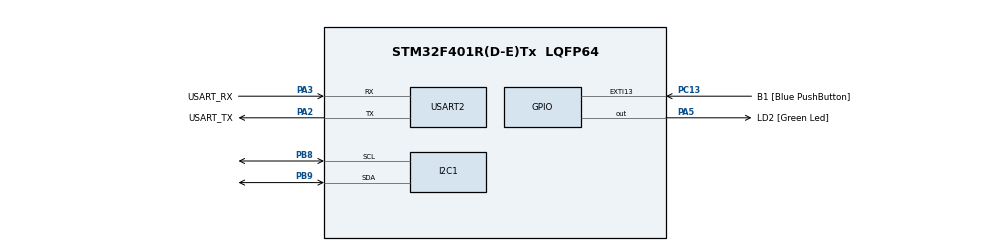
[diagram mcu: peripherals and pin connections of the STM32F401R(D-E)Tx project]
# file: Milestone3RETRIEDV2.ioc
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Mcu.Family=STM32F4
Mcu.Name=STM32F401R(D-E)Tx
Mcu.Package=LQFP64
NVIC.PriorityGroup=NVIC_PRIORITYGROUP_4
PA13.GPIO_Label=TMS
PA13.Mode=Trace_Asynchronous_SW
PA13.Signal=SYS_JTMS-SWDIO
PA14.GPIO_Label=TCK
PA14.Mode=Trace_Asynchronous_SW
PA14.Signal=SYS_JTCK-SWCLK
PA2.GPIO_Label=USART_TX
PA2.GPIO_Mode=GPIO_MODE_AF_PP
PA2.GPIO_PuPd=GPIO_NOPULL
PA2.GPIO_Speed=GPIO_SPEED_FREQ_LOW
PA2.Mode=Asynchronous
PA2.Signal=USART2_TX
PA3.GPIO_Label=USART_RX
PA3.GPIO_Mode=GPIO_MODE_AF_PP
PA3.GPIO_PuPd=GPIO_NOPULL
PA3.GPIO_Speed=GPIO_SPEED_FREQ_LOW
PA3.Mode=Asynchronous
PA3.Signal=USART2_RX
PA5.GPIO_Label=LD2 [Green Led]
PA5.GPIO_Mode=GPIO_MODE_OUTPUT_PP
PA5.GPIO_PuPd=GPIO_NOPULL
PA5.GPIO_Speed=GPIO_SPEED_FREQ_LOW
PA5.Signal=GPIO_Output
PB3.GPIO_Label=SWO
PB3.Mode=Trace_Asynchronous_SW
PB3.Signal=SYS_JTDO-SWO
PB8.Mode=I2C
PB8.Signal=I2C1_SCL
PB9.Mode=I2C
PB9.Signal=I2C1_SDA
PC13-ANTI_TAMP.GPIO_Label=B1 [Blue PushButton]
PC13-ANTI_TAMP.GPIO_ModeDefaultEXTI=GPIO_MODE_IT_FALLING
PC13-ANTI_TAMP.GPIO_PuPd=GPIO_NOPULL
PC13-ANTI_TAMP.Signal=GPXTI13
PC14-OSC32_IN.Mode=LSE-External-Oscillator
PC14-OSC32_IN.Signal=RCC_OSC32_IN
PC15-OSC32_OUT.Mode=LSE-External-Oscillator
PC15-OSC32_OUT.Signal=RCC_OSC32_OUT
PH0\ -\ OSC_IN.Mode=HSE-External-Clock-Source
PH0\ -\ OSC_IN.Signal=RCC_OSC_IN
PH1\ -\ OSC_OUT.Mode=HSE-External-Clock-Source
PH1\ -\ OSC_OUT.Signal=RCC_OSC_OUT
ProjectManager.HeapSize=0x200
ProjectManager.StackSize=0x400
ProjectManager.TargetToolchain=Makefile
RCC.48MHZClocksFreq_Value=48000000
RCC.AHBFreq_Value=84000000
RCC.APB1CLKDivider=RCC_HCLK_DIV2
RCC.APB1Freq_Value=42000000
RCC.APB1TimFreq_Value=84000000
RCC.APB2Freq_Value=84000000
RCC.APB2TimFreq_Value=84000000
RCC.CortexFreq_Value=84000000
RCC.HCLKFreq_Value=84000000
RCC.HSE_VALUE=8000000
RCC.HSI_VALUE=16000000
RCC.PLLN=336
RCC.PLLP=RCC_PLLP_DIV4
RCC.PLLQ=7
RCC.SYSCLKFreq_VALUE=84000000
RCC.SYSCLKSource=RCC_SYSCLKSOURCE_PLLCLK
RCC.VCOOutputFreq_Value=336000000
USART2.VirtualMode=VM_ASYNC
board=NUCLEO-F401RE

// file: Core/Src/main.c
/* USER CODE BEGIN Header */
/**
  ******************************************************************************
  * @file           : main.c
  * @brief          : Main program body
  ******************************************************************************
  * @attention
  *
  * Copyright (c) 2026 STMicroelectronics.
  * All rights reserved.
  *
  * This software is licensed under terms that can be found in the LICENSE file
  * in the root directory of this software component.
  * If no LICENSE file comes with this software, it is provided AS-IS.
  *
  ******************************************************************************
  */
/* USER CODE END Header */
#include "main.h"
#include <string.h>
#include <stddef.h>
#include <stdbool.h>

void SystemClock_Config(void);
static void MX_GPIO_Init(void);
static void MX_I2C1_Init(void);
static void MX_USART2_UART_Init(void);
void UART_SendAndReadData(USART_TypeDef *USARTX, const uint8_t *data, size_t length);
void I2C_Bus_Recovery();

typedef enum {
  ERROR_TIMEOUT,
  ERROR_NACK,
  ERROR_BUS_STUCK,
  I2C_SUCCESS
  } I2C_Status;

  I2C_Status I2C_Wait_With_Timeout(uint32_t, uint32_t);

#define I2C_TIMEOUT_CYCLES 144000
int main(void)
{

  /* MCU Configuration--------------------------------------------------------*/

  /* Reset of all peripherals, Initializes the Flash interface and the Systick. */
  LL_APB2_GRP1_EnableClock(LL_APB2_GRP1_PERIPH_SYSCFG);
  LL_APB1_GRP1_EnableClock(LL_APB1_GRP1_PERIPH_PWR);

  /* System interrupt init*/
  NVIC_SetPriorityGrouping(NVIC_PRIORITYGROUP_4);

  /* Configure the system clock */
  SystemClock_Config();

  /* Initialize all configured peripherals */
  MX_GPIO_Init();
  MX_I2C1_Init();
  MX_USART2_UART_Init();

  CoreDebug->DEMCR |= CoreDebug_DEMCR_TRCENA_Msk;
  DWT->CTRL |= DWT_CTRL_CYCCNTENA_Msk;
  DWT -> CYCCNT = 0;
  const char *msg = "System booting..\n";
  UART_SendAndReadData(USART2, (const uint8_t *)msg, strlen(msg));
  /* Infinite loop */
  /* USER CODE BEGIN WHILE */
  if (!LL_I2C_IsEnabled(I2C1)){
      LL_I2C_Enable(I2C1);
    }

  while (1)
  {
    /* USER CODE END WHILE */

    uint32_t busy_timeout = DWT->CYCCNT;
    while (LL_I2C_IsActiveFlag_BUSY(I2C1)){
      if ((DWT->CYCCNT - busy_timeout) >= I2C_TIMEOUT_CYCLES){
        msg = "ERROR: Bus stuck BUSY upon entry, trying to free it...\n";
        UART_SendAndReadData(USART2, (const uint8_t * )msg, strlen(msg));
        I2C_Bus_Recovery();
        break;
      }
    }

    LL_I2C_GenerateStartCondition(I2C1);

    if (I2C_Wait_With_Timeout(LL_I2C_SR1_SB, I2C_TIMEOUT_CYCLES) != I2C_SUCCESS){
      msg = "ERROR: START CONDITION Timeout! \n";
      UART_SendAndReadData(USART2, (const uint8_t *)msg, strlen(msg));
      I2C_Bus_Recovery();
      LL_mDelay(50); // retry loop...
      continue;
    } // already checking...

    msg = "Start Condition Detected..\n";
    UART_SendAndReadData(USART2, (const uint8_t *)msg, strlen(msg));

    volatile uint8_t shifted = 0x48 << 1;
  LL_I2C_TransmitData8(I2C1, shifted);
  shifted = 0x00;

  uint32_t add_start = DWT -> CYCCNT;
  bool add_ok = false;

  while ((DWT->CYCCNT - add_start) < I2C_TIMEOUT_CYCLES){
  if (LL_I2C_IsActiveFlag_AF(I2C1)){
        msg = "ERROR: NACK not detected...";
        UART_SendAndReadData(USART2, (const uint8_t * )msg, strlen(msg));
        LL_I2C_ClearFlag_AF(I2C1);
        LL_I2C_GenerateStopCondition(I2C1);
        break;
      }
      if (LL_I2C_IsActiveFlag_ADDR(I2C1)){
        LL_I2C_ClearFlag_ADDR(I2C1);
        add_ok = true;
        break;
      }
    }

    if (!add_ok){
      msg = "ERROR: Address Timeout or NACK, recovering..\n";
      UART_SendAndReadData(USART2, (const uint8_t *)msg, strlen(msg));
      I2C_Bus_Recovery();
      LL_mDelay(50);
      continue;
    }

    msg = "Address Detected!\n";
    UART_SendAndReadData(USART2, (const uint8_t *)msg, strlen(msg));

    LL_I2C_TransmitData8(I2C1, 0x69);

    if (I2C_Wait_With_Timeout(LL_I2C_SR1_BTF, I2C_TIMEOUT_CYCLES) != I2C_SUCCESS){
      msg = "ERROR: First Byte Transmission Failed (BTF Timeout).\n";
      UART_SendAndReadData(USART2, (const uint8_t *)msg, strlen(msg));
      I2C_Bus_Recovery();
      LL_mDelay(50);
      continue;
    }

    msg = "1st Message Sent!...\n";
    UART_SendAndReadData(USART2, (const uint8_t *)msg, strlen(msg));

    LL_I2C_TransmitData8(I2C1, 0x00);

    if (I2C_Wait_With_Timeout(LL_I2C_SR1_BTF, I2C_TIMEOUT_CYCLES) != I2C_SUCCESS){
      msg = "ERROR: Second Byte Transmission Failed (BTF Timeout).\n";
      UART_SendAndReadData(USART2, (const uint8_t *)msg, strlen(msg));
      I2C_Bus_Recovery();
      LL_mDelay(50);
      continue;
    }

    msg = "2nd Message Sent!...\n";
    UART_SendAndReadData(USART2, (const uint8_t *)msg, strlen(msg));

  // do nothing while busy
  /* Infinite loop */
  /* USER CODE BEGIN WHILE */

  // normally SDA and SCL lines are highest here

  // unless start bit is active, program wont proceed

  // program transmission

  /*
  while (!LL_I2C_IsActiveFlag_ADDR(I2C1) && !LL_I2C_IsActiveFlag_AF(I2C1)){

  }
  // waits until either condition is reached

  // failed condition, no address detected
  if (LL_I2C_IsActiveFlag_AF(I2C1)){
     msg = "ERROR: NACK: Address not detected...\n";
    UART_SendAndReadData(USART2, (const uint8_t *)msg, strlen(msg));
      LL_I2C_GenerateStopCondition(I2C1);
     // while(LL_I2C_IsActiveFlag_STOP(I2C1));
      LL_I2C_ClearFlag_AF(I2C1);
      // LL_GPIO_ResetOutputPin(GPIOA, LL_GPIO_PIN_5);
      break;
    } else {
       msg = "Address Detected!..\n";
       UART_SendAndReadData(USART2, (const uint8_t *)msg, strlen(msg));
      // an address was detected!
      volatile uint32_t temp;
      temp = I2C1 -> SR1;
      temp = I2C1 -> SR2;
      (void)temp;
      */ /*
      LL_I2C_ClearFlag_ADDR(I2C1);

      LL_I2C_TransmitData8(I2C1, shifted);
      while(!LL_I2C_IsActiveFlag_BTF(I2C1)){}

      LL_I2C_TransmitData8(I2C1, 0x69);

      while(!LL_I2C_IsActiveFlag_BTF(I2C1)){}

      if (I2C_Wait_With_Timeout(LL_I2C_SR1_TXE, 14400) != I2C_SUCCESS){
        msg = "ERROR: Second Byte Transmission Failed. \n";
        UART_SendAndReadData(USART2, (const uint8_t *)msg, strlen(msg));
        LL_I2C_GenerateStopCondition(I2C1);
        LL_mDelay(50);
      }else {
        msg = "1st Data Sent!..\n";
      UART_SendAndReadData(USART2, (const uint8_t *)msg, strlen(msg));
      }

      shifted = 0x00;

      LL_I2C_TransmitData8(I2C1, shifted);

      while(!LL_I2C_IsActiveFlag_BTF(I2C1)){}

      if (I2C_Wait_With_Timeout(LL_I2C_SR1_TXE, 14400) != I2C_SUCCESS){
        msg = "ERROR : Second Byte Transmission Failed. \n";
        UART_SendAndReadData(USART2, (const uint8_t *)msg, strlen(msg));
        LL_I2C_GenerateStopCondition(I2C1);
        LL_mDelay(50);
      }else {
        msg = "2nd Data Sent!..\n";
      UART_SendAndReadData(USART2, (const uint8_t *)msg, strlen(msg));
      }

      LL_I2C_GenerateStopCondition(I2C1);
      // while(!LL_I2C_IsActiveFlag_STOP(I2C1));

      while(LL_I2C_IsActiveFlag_BUSY(I2C1)){}
      // LL_GPIO_SetOutputPin(GPIOA, LL_GPIO_PIN_5);
    }
    */

    LL_I2C_GenerateStopCondition(I2C1);
    while(LL_I2C_IsActiveFlag_BUSY(I2C1)){}

    /* USER CODE BEGIN 3 */
    msg = "Stop Condition Generated..\n";
    UART_SendAndReadData(USART2, (const uint8_t *)msg, strlen(msg));

    // LL_I2C_GenerateStopCondition(I2C1);

    LL_mDelay(500);
  }
  /* USER CODE END 3 */
}

void UART_SendAndReadData(USART_TypeDef *USARTX, const uint8_t *data, size_t length){

  for (size_t i = 0; i < length; i++){
   while (!LL_USART_IsActiveFlag_TXE(USARTX));
   LL_USART_TransmitData8(USARTX, data[i]);
   //while(!LL_USART_IsActiveFlag_RXNE(USART1)){}
  //  LL_USART_ReceiveData8(USART1);
  }
  while (!LL_USART_IsActiveFlag_TC(USARTX)){}
  //while(!LL_USART_IsActiveFlag_RXNE(USART1)){}
  //LL_USART_ReceiveData8(USART1);
}

I2C_Status I2C_Wait_With_Timeout(uint32_t Flag, uint32_t TimeoutCycles){
  uint32_t start_cycle = DWT-> CYCCNT;

  while ((I2C1 ->SR1 & Flag)==0){

    if ((DWT->CYCCNT) - start_cycle >= TimeoutCycles){
      return ERROR_TIMEOUT;
    }

    else if (LL_I2C_IsActiveFlag_AF(I2C1)){
      LL_I2C_ClearFlag_AF(I2C1);

     // LL_I2C_IsActiveFlag_AF(I2C1);

      return ERROR_NACK;
    }
  }

  return I2C_SUCCESS;
}

void I2C_Bus_Recovery(){
  LL_I2C_Disable(I2C1); // disables the I2C peripheral from running

      LL_GPIO_SetPinOutputType(GPIOB, LL_GPIO_PIN_6, LL_GPIO_OUTPUT_OPENDRAIN); // sets SCL as open_drain
      LL_GPIO_SetPinMode(GPIOB, LL_GPIO_PIN_6, LL_GPIO_MODE_OUTPUT); // SCL becomes the output while SDA becomes the input
      LL_GPIO_SetPinMode(GPIOB, LL_GPIO_PIN_7, LL_GPIO_MODE_INPUT);

      // we essentially need to toggle SCL 9 times as there are 8 bits in a byte + the one bit for ACK
      // since the SCL line is left high if the master glitches (for whatever reason), the SDA is clamped to 0 until it detects
      // the SCL line moving up or down
      // Ultimately, this is done until the SDA line is detected to be logic 1, as that would signify the SCL bit that held it down
      // would have been released, thus recovering the bus.
      for (int i = 0; i < 9; i++){
        LL_GPIO_ResetOutputPin(GPIOB, LL_GPIO_PIN_6);
        LL_mDelay(5);
        LL_GPIO_SetOutputPin(GPIOB, LL_GPIO_PIN_6);
        LL_mDelay(5);
        if (LL_GPIO_IsInputPinSet(GPIOB, LL_GPIO_PIN_7)){
          break;
        }
      }
      // In the above for loop, the SDA line is set as an input so that it can be monitored, below its turned into an output
      // so that we can create a STOP condition for this byte, hence allowing both SDA and SCL lines to be reset.

      LL_GPIO_SetPinOutputType(GPIOB, LL_GPIO_PIN_7, LL_GPIO_OUTPUT_OPENDRAIN);
      LL_GPIO_SetPinMode(GPIOB, LL_GPIO_PIN_7, LL_GPIO_MODE_OUTPUT);

      LL_GPIO_ResetOutputPin(GPIOB, LL_GPIO_PIN_6); // SCL LOW
      LL_GPIO_ResetOutputPin(GPIOB, LL_GPIO_PIN_7); // SDA LOW

      LL_mDelay(1);
      LL_GPIO_SetOutputPin(GPIOB, LL_GPIO_PIN_6); // SCL HIGH
      LL_mDelay(1);
      LL_GPIO_SetOutputPin(GPIOB, LL_GPIO_PIN_7); // SDA HIGH
      LL_mDelay(5);

      // LL_GPIO_SetPinOutputType(GPIOB, LL_GPIO_PIN_7, LL_GPIO_OUTPUT_OPENDRAIN);
      LL_GPIO_SetPinOutputType(GPIOB, LL_GPIO_PIN_6, LL_GPIO_OUTPUT_OPENDRAIN);

      // configuring back SCL and SDA lines to their previous arrangements...
      LL_GPIO_SetPinMode(GPIOB, LL_GPIO_PIN_6, LL_GPIO_MODE_ALTERNATE);
      LL_GPIO_SetPinMode(GPIOB, LL_GPIO_PIN_7, LL_GPIO_MODE_ALTERNATE);

      LL_GPIO_SetAFPin_0_7(GPIOB, LL_GPIO_PIN_6, LL_GPIO_AF_4);
      LL_GPIO_SetAFPin_0_7(GPIOB, LL_GPIO_PIN_7, LL_GPIO_AF_4);

      LL_I2C_EnableReset(I2C1);
      LL_I2C_DisableReset(I2C1);

      MX_I2C1_Init();
      LL_I2C_Enable(I2C1);
}

void SystemClock_Config(void)
{
  LL_FLASH_SetLatency(LL_FLASH_LATENCY_2);
  while(LL_FLASH_GetLatency()!= LL_FLASH_LATENCY_2)
  {
  }
  LL_PWR_SetRegulVoltageScaling(LL_PWR_REGU_VOLTAGE_SCALE2);
  LL_RCC_HSI_SetCalibTrimming(16);
  LL_RCC_HSI_Enable();

   /* Wait till HSI is ready */
  while(LL_RCC_HSI_IsReady() != 1)
  {

  }
  LL_RCC_PLL_ConfigDomain_SYS(LL_RCC_PLLSOURCE_HSI, LL_RCC_PLLM_DIV_16, 336, LL_RCC_PLLP_DIV_4);
  LL_RCC_PLL_Enable();

   /* Wait till PLL is ready */
  while(LL_RCC_PLL_IsReady() != 1)
  {

  }
  while (LL_PWR_IsActiveFlag_VOS() == 0)
  {
  }
  LL_RCC_SetAHBPrescaler(LL_RCC_SYSCLK_DIV_1);
  LL_RCC_SetAPB1Prescaler(LL_RCC_APB1_DIV_2);
  LL_RCC_SetAPB2Prescaler(LL_RCC_APB2_DIV_1);
  LL_RCC_SetSysClkSource(LL_RCC_SYS_CLKSOURCE_PLL);

   /* Wait till System clock is ready */
  while(LL_RCC_GetSysClkSource() != LL_RCC_SYS_CLKSOURCE_STATUS_PLL)
  {

  }
  LL_Init1msTick(84000000);
  LL_SetSystemCoreClock(84000000);
  LL_RCC_SetTIMPrescaler(LL_RCC_TIM_PRESCALER_TWICE);
}

static void MX_I2C1_Init(void)
{

  LL_I2C_InitTypeDef I2C_InitStruct = {0};

  LL_GPIO_InitTypeDef GPIO_InitStruct = {0};

  LL_AHB1_GRP1_EnableClock(LL_AHB1_GRP1_PERIPH_GPIOB);
  /**I2C1 GPIO Configuration
  PB8   ------> I2C1_SCL
  PB9   ------> I2C1_SDA
  */
  GPIO_InitStruct.Pin = LL_GPIO_PIN_8|LL_GPIO_PIN_9;
  GPIO_InitStruct.Mode = LL_GPIO_MODE_ALTERNATE;
  GPIO_InitStruct.Speed = LL_GPIO_SPEED_FREQ_VERY_HIGH;
  GPIO_InitStruct.OutputType = LL_GPIO_OUTPUT_OPENDRAIN;
  GPIO_InitStruct.Pull = LL_GPIO_PULL_NO;
  GPIO_InitStruct.Alternate = LL_GPIO_AF_4;
  LL_GPIO_Init(GPIOB, &GPIO_InitStruct);

  /* Peripheral clock enable */
  LL_APB1_GRP1_EnableClock(LL_APB1_GRP1_PERIPH_I2C1);

  /** I2C Initialization
  */
  LL_I2C_DisableOwnAddress2(I2C1);
  LL_I2C_DisableGeneralCall(I2C1);
  LL_I2C_EnableClockStretching(I2C1);
  I2C_InitStruct.PeripheralMode = LL_I2C_MODE_I2C;
  I2C_InitStruct.ClockSpeed = 100000;
  I2C_InitStruct.DutyCycle = LL_I2C_DUTYCYCLE_2;
  I2C_InitStruct.OwnAddress1 = 0;
  I2C_InitStruct.TypeAcknowledge = LL_I2C_ACK;
  I2C_InitStruct.OwnAddrSize = LL_I2C_OWNADDRESS1_7BIT;
  LL_I2C_Init(I2C1, &I2C_InitStruct);
  LL_I2C_SetOwnAddress2(I2C1, 0);

}

static void MX_USART2_UART_Init(void)
{

  LL_USART_InitTypeDef USART_InitStruct = {0};

  LL_GPIO_InitTypeDef GPIO_InitStruct = {0};

  /* Peripheral clock enable */
  LL_APB1_GRP1_EnableClock(LL_APB1_GRP1_PERIPH_USART2);

  LL_AHB1_GRP1_EnableClock(LL_AHB1_GRP1_PERIPH_GPIOA);
  /**USART2 GPIO Configuration
  PA2   ------> USART2_TX
  PA3   ------> USART2_RX
  */
  GPIO_InitStruct.Pin = USART_TX_Pin|USART_RX_Pin;
  GPIO_InitStruct.Mode = LL_GPIO_MODE_ALTERNATE;
  GPIO_InitStruct.Speed = LL_GPIO_SPEED_FREQ_LOW;
  GPIO_InitStruct.OutputType = LL_GPIO_OUTPUT_PUSHPULL;
  GPIO_InitStruct.Pull = LL_GPIO_PULL_NO;
  GPIO_InitStruct.Alternate = LL_GPIO_AF_7;
  LL_GPIO_Init(GPIOA, &GPIO_InitStruct);

  USART_InitStruct.BaudRate = 115200;
  USART_InitStruct.DataWidth = LL_USART_DATAWIDTH_8B;
  USART_InitStruct.StopBits = LL_USART_STOPBITS_1;
  USART_InitStruct.Parity = LL_USART_PARITY_NONE;
  USART_InitStruct.TransferDirection = LL_USART_DIRECTION_TX_RX;
  USART_InitStruct.HardwareFlowControl = LL_USART_HWCONTROL_NONE;
  USART_InitStruct.OverSampling = LL_USART_OVERSAMPLING_16;
  LL_USART_Init(USART2, &USART_InitStruct);
  LL_USART_ConfigAsyncMode(USART2);
  LL_USART_Enable(USART2);

}

static void MX_GPIO_Init(void)
{
  LL_EXTI_InitTypeDef EXTI_InitStruct = {0};
  LL_GPIO_InitTypeDef GPIO_InitStruct = {0};

  /* GPIO Ports Clock Enable */
  LL_AHB1_GRP1_EnableClock(LL_AHB1_GRP1_PERIPH_GPIOC);
  LL_AHB1_GRP1_EnableClock(LL_AHB1_GRP1_PERIPH_GPIOH);
  LL_AHB1_GRP1_EnableClock(LL_AHB1_GRP1_PERIPH_GPIOA);
  LL_AHB1_GRP1_EnableClock(LL_AHB1_GRP1_PERIPH_GPIOB);

  /**/
  LL_GPIO_ResetOutputPin(LD2_GPIO_Port, LD2_Pin);

  /**/
  LL_SYSCFG_SetEXTISource(LL_SYSCFG_EXTI_PORTC, LL_SYSCFG_EXTI_LINE13);

  /**/
  EXTI_InitStruct.Line_0_31 = LL_EXTI_LINE_13;
  EXTI_InitStruct.LineCommand = ENABLE;
  EXTI_InitStruct.Mode = LL_EXTI_MODE_IT;
  EXTI_InitStruct.Trigger = LL_EXTI_TRIGGER_FALLING;
  LL_EXTI_Init(&EXTI_InitStruct);

  /**/
  LL_GPIO_SetPinPull(B1_GPIO_Port, B1_Pin, LL_GPIO_PULL_NO);

  /**/
  LL_GPIO_SetPinMode(B1_GPIO_Port, B1_Pin, LL_GPIO_MODE_INPUT);

  /**/
  GPIO_InitStruct.Pin = LD2_Pin;
  GPIO_InitStruct.Mode = LL_GPIO_MODE_OUTPUT;
  GPIO_InitStruct.Speed = LL_GPIO_SPEED_FREQ_LOW;
  GPIO_InitStruct.OutputType = LL_GPIO_OUTPUT_PUSHPULL;
  GPIO_InitStruct.Pull = LL_GPIO_PULL_NO;
  LL_GPIO_Init(LD2_GPIO_Port, &GPIO_InitStruct);

}

void Error_Handler(void)
{
  __disable_irq();
  while (1)
  {
  }
}
